# PIC18F56Q24 register map
Vendor: Microchip
Registers are 8-bit, read-write, reset 0x0 unless marked. A register's access mark holds for its fields unless they carry their own. Addresses are absolute, and some are shared; only a register's first bit layout is shown; [hi:lo] are bit positions; {n}, {i} and the like mark numbered series.

## cla_clc
0xD5 CLCSELECT
  [2:0] SLCT
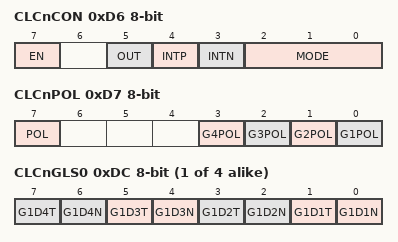
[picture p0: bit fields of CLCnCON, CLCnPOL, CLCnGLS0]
0xD6 CLCnCON — Configurable logic cell control
  [7] EN, [5] OUT ro, [4] INTP, [3] INTN, [2:0] MODE
0xD7 CLCnPOL reset not defined — Polarity control (power-on value 0---xxxx)
  [7] POL, [n-1] G{n}POL (n=1..4)
{0xD8+i} CLCnSEL{i} reset not defined (i=0..3) — Input select register 1 (power-on value --xxxxxx)
  [5:0] D{i+1}S
{0xDC+i} CLCnGLS{i} reset not defined (i=0..3) — Gate logic select register {i} (power-on value xxxxxxxx)
  [2n-1] G{i+1}D{n}T (n=1..4), [2n-2] G{i+1}D{n}N (n=1..4)

## dma
0xE7 DMASELECT — DMA instance selection register
  [1:0] SLCT
0xE8 DMAnBUF ro reset not defined — DMA data buffer (power-on value xxxxxxxx)
  [7:0] BUF
0xE9 DMAnDCNTL
  [7:0] DCNT
0xEA DMAnDCNTH
  [3:0] DCNT
0xEB DMAnDPTRL ro
  [7:0] DPTR
0xEC DMAnDPTRH ro
  [7:0] DPTR
0xED DMAnDSZL reset not defined — (power-on value xxxxxxxx)
  [7:0] DSZ
0xEE DMAnDSZH
  [3:0] DSZ
0xEF DMAnDSAL reset not defined — (power-on value xxxxxxxx)
  [7:0] DSA
0xF0 DMAnDSAH
  [7:0] DSA
0xF1 DMAnSCNTL
  [7:0] SCNT
0xF2 DMAnSCNTH
  [3:0] SCNT
0xF3 DMAnSPTRL ro
  [7:0] SPTR
0xF4 DMAnSPTRH ro
  [7:0] SPTR
0xF5 DMAnSPTRU ro
  [5:0] SPTR
0xF6 DMAnSSZL
  [7:0] SSZ
0xF7 DMAnSSZH
  [3:0] SSZ
0xF8 DMAnSSAL
  [7:0] SSA
0xF9 DMAnSSAH
  [7:0] SSA
0xFA DMAnSSAU
  [5:0] SSA
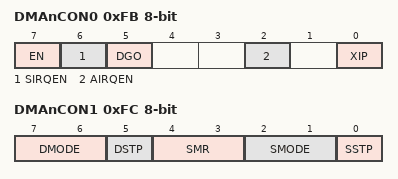
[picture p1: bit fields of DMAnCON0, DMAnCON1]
0xFB DMAnCON0 — DMA control register 0
  [7] EN, [6] SIRQEN, [5] DGO, [2] AIRQEN, [0] XIP ro
0xFC DMAnCON1 — DMA control register 1
  [7:6] DMODE, [5] DSTP, [4:3] SMR, [2:1] SMODE, [0] SSTP
0xFD DMAnAIRQ — DMA abort trigger selection register
  [7:0] AIRQ
0xFE DMAnSIRQ — DMA start trigger selection register
  [7:0] SIRQ

## io_vport
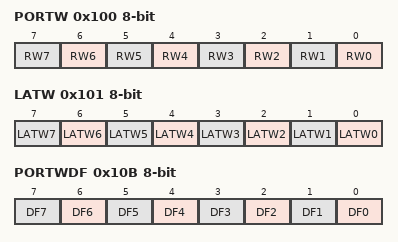
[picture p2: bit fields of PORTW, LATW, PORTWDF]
0x100 PORTW
  [n] RW{n} (n=0..7)
0x101 LATW
  [n] LATW{n} (n=0..7)
{0x102+i} PORTWIN{i} (i=0..7)
  [3:0] IN
0x10A PORTWCLK — Virtual Port Control Register
  [4:0] CLK
0x10B PORTWDF
  [n] DF{n} (n=0..7)
0x10C PORTWCON
  [0] CLKEN

## adc_sarcore_mp_ctrl
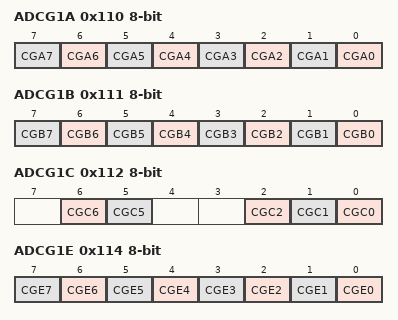
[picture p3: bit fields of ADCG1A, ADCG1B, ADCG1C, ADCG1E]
0x110 ADCG1A — ADC CHANNEL GROUP A REGISTER
  [n] CGA{n} (n=0..7)
0x111 ADCG1B — ADC CHANNEL GROUP B REGISTER
  [n] CGB{n} (n=0..7)
0x112 ADCG1C — ADC CHANNEL GROUP C REGISTER
  [6] CGC6, [5] CGC5, [2] CGC2, [1] CGC1, [0] CGC0
0x114 ADCG1E — ADC CHANNEL GROUP C REGISTER
  [n] CGE{n} (n=0..7)
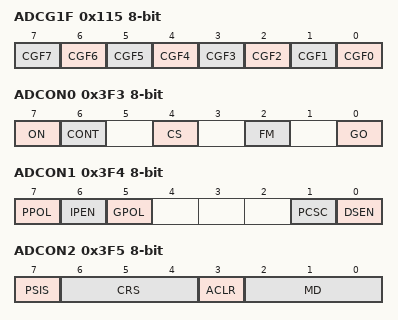
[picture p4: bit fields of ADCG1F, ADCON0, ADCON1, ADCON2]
0x115 ADCG1F — ADC CHANNEL GROUP C REGISTER
  [n] CGF{n} (n=0..7)
0x3D9 ADLTHL
  [7:0] LTH
0x3DA ADLTHH
  [7:0] LTH
0x3DB ADUTHL
  [7:0] UTH
0x3DC ADUTHH
  [7:0] UTH
0x3DD ADERRL ro reset not defined — (power-on value xxxxxxxx)
  [7:0] ERR
0x3DE ADERRH ro reset not defined — (power-on value xxxxxxxx)
  [7:0] ERR
0x3DF ADSTPTL
  [7:0] STPT
0x3E0 ADSTPTH
  [7:0] STPT
0x3E1 ADFLTRL ro reset not defined — (power-on value xxxxxxxx)
  [7:0] FLTR
0x3E2 ADFLTRH ro reset not defined — (power-on value xxxxxxxx)
  [7:0] FLTR
0x3E3 ADACCL reset not defined — (power-on value xxxxxxxx)
  [7:0] ACC
0x3E4 ADACCH reset not defined — (power-on value xxxxxxxx)
  [7:0] ACC
0x3E6 ADCNT
  [7:0] CNT
0x3E7 ADRPT
  [7:0] RPT
0x3E8 ADPREVL ro reset not defined — (power-on value xxxxxxxx)
  [7:0] PREV
0x3E9 ADPREVH ro reset not defined — (power-on value xxxxxxxx)
  [7:0] PREV
0x3EA ADRESL reset not defined — (power-on value xxxxxxxx)
  [7:0] RES
0x3EB ADRESH reset not defined — (power-on value xxxxxxxx)
  [7:0] RES
0x3EC ADPCH
  [7:0] PCH
0x3ED ADNCH
  [7:0] NCH
0x3EE ADACQL
  [7:0] ACQ
0x3EF ADACQH
  [4:0] ACQ
0x3F0 ADCAP
  [4:0] CAP
0x3F1 ADPREL
  [7:0] PRE
0x3F2 ADPREH
  [4:0] PRE
0x3F3 ADCON0
  [7] ON, [6] CONT, [4] CS, [2] FM, [0] GO
0x3F4 ADCON1
  [7] PPOL, [6] IPEN, [5] GPOL, [1] PCSC, [0] DSEN
0x3F5 ADCON2
  [7] PSIS, [6:4] CRS, [3] ACLR, [2:0] MD
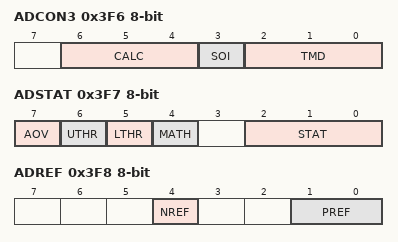
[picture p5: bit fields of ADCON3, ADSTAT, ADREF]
0x3F6 ADCON3
  [6:4] CALC, [3] SOI, [2:0] TMD
0x3F7 ADSTAT
  [7] AOV ro
  [6] UTHR ro
  [5] LTHR ro
  [4] MATH — (can only be cleared)
  [2:0] STAT ro
0x3F8 ADREF
  [4] NREF, [1:0] PREF
0x3F9 ADACT
  [5:0] ACT
0x3FA ADCLK
  [5:0] CS
